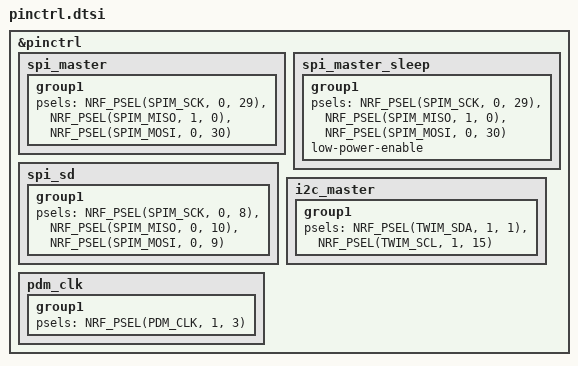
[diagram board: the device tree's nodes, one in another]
&pinctrl {
    spi_master: spi_master {
        group1 {
            psels = <NRF_PSEL(SPIM_SCK, 0, 29)>,
                <NRF_PSEL(SPIM_MISO, 1, 0)>,
                <NRF_PSEL(SPIM_MOSI, 0, 30)>;
        };
    };

    spi_master_sleep: spi_master_sleep {
        group1 {
            psels = <NRF_PSEL(SPIM_SCK, 0, 29)>,
                <NRF_PSEL(SPIM_MISO, 1, 0)>,
                <NRF_PSEL(SPIM_MOSI, 0, 30)>;
            low-power-enable;
        };
    };

    spi_sd: spi_sd {
        group1 {
            psels = <NRF_PSEL(SPIM_SCK, 0, 8)>,
                <NRF_PSEL(SPIM_MISO, 0, 10)>,
                <NRF_PSEL(SPIM_MOSI, 0, 9)>;
        };
    };

    i2c_master: i2c_master {
        group1 {
            psels = <NRF_PSEL(TWIM_SDA, 1, 1)>,
                <NRF_PSEL(TWIM_SCL, 1, 15)>;
        };
    };

    pdm_clk: pdm_clk {
        group1 {
            psels = <NRF_PSEL(PDM_CLK, 1, 3)>;
        };
    };
};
